# M460_v1 register map
File version: 1.0
Registers are 32-bit, read-write, reset 0x0 unless marked. A register's access mark holds for its fields unless they carry their own. Offsets are from the block's base; [hi:lo] are bit positions; 'fields as' and 'values as' point back to an identical list.

## HSUSBH — USBH Register Map
Base 0x4001A000
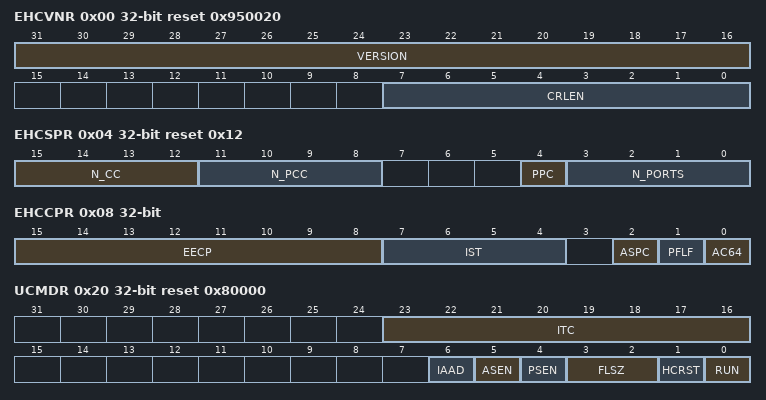
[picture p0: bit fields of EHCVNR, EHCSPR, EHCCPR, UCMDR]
0x00 EHCVNR ro reset 0x950020 — EHCI Version Number Register
  [31:16] VERSION — Host Controller Interface Version Number. This is a two-byte register containing a BCD encoding of the EHCI revision number supported by this host controller. The most significant byte of this register represents a major revision and the least significant byte is the minor revision.
  [7:0] CRLEN — Capability Registers Length. This register is used as an offset to add to register base to find the beginning of the Operational Register Space.
0x04 EHCSPR ro reset 0x12 — EHCI Structural Parameters Register
  [15:12] N_CC — Number of Companion Controller. This field indicates the number of companion controllers associated with this USB 2.0 host controller. A 0 in this field indicates there are no companion host controllers. Port-ownership hand-off is not supported. Only high-speed devices are supported on the host controller root ports. A value larger than 0 in this field indicates there are companion USB 1.1 host controller(s). Port-ownership hand-offs are supported. High, Full- and Low-speed devices are supported on the host controller root ports.
  [11:8] N_PCC — Number of Ports Per Companion Controller. This field indicates the number of ports supported per companion host controller. It is used to indicate the port routing configuration to system software. For example, if N_PORTS has a value of 6 and N_CC has a value of 2 then N_PCC could have a value of 3. The convention is that the first N_PCC ports are assumed to be routed to companion controller 1, the next N_PCC ports to companion controller 2, etc. In the previous example, the N_PCC could have been 4, where the first 4 are routed to companion controller 1 and the last two are routed to companion controller 2. The number in this field must be consistent with N_PORTS and N_CC.
  [4] PPC — Port Power Control. This field indicates whether the host controller implementation includes port power control. A 1 in this bit indicates the ports have port power switches. A 0 in this bit indicates the port do not have port power stitches. The value of this field affects the functionality of the Port Power field in each port status and control register.
  [3:0] N_PORTS — Number of Physical Downstream Ports. This field specifies the number of physical downstream ports implemented on this host controller. The value of this field determines how many port registers are addressable in the Operational Register Space (see Table 2-8). Valid values are in the range of 1H to FH. A 0 in this field is undefined.
0x08 EHCCPR ro — EHCI Capability Parameters Register
  [15:8] EECP — EHCI Extended Capabilities Pointer
    0=No extended capabilities are implemented
  [7:4] IST — Isochronous Scheduling Threshold. This field indicates, relative to the current position of the executing host controller, where software can reliably update the isochronous schedule. When bit [7] is 0, the value of the least significant 3 bits indicates the number of micro-frames a host controller can hold a set of isochronous data structures (one or more) before flushing the state.
  [2] ASPC — Asynchronous Schedule Park Capability
    0=This EHCI host controller doesn't support park feature of high-speed queue heads in the Asynchronous Schedule
  [1] PFLF — Programmable Frame List Flag
    0=System software must use a frame list length of 1024 elements with this EHCI host controller
  [0] AC64 — 64-bit Addressing Capability
    0=Data structure using 32-bit address memory pointers
0x20 UCMDR reset 0x80000 — USB Command Register
  [23:16] ITC — Interrupt Threshold Control (Read/Write). This field is used by system software to select the maximum rate at which the host controller will issue interrupts. The only valid values are defined below. If software writes an invalid value to this register, the results are undefined. Value Maximum Interrupt Interval. Any other value in this register yields undefined results. Software modifications to this bit while HCHalted bit is equal to 0 results in undefined behavior.
    1=1 micro-frame; 2=2 micro-frames; 4=4 micro-frames; 8=8 micro-frames (default, equates to 1 ms); 16=16 micro-frames (2 ms); 32=32 micro-frames (4 ms); 64=64 micro-frames (8 ms)
  [6] IAAD — Interrupt on Asynchronous Advance Doorbell (Read/Write). This bit is used as a doorbell by software to tell the host controller to issue an interrupt the next time it advances asynchronous schedule. Software must write a 1 to this bit to ring the doorbell. When the host controller has evicted all appropriate cached schedule state, it sets the Interrupt on Asynchronous Advance status bit in the USTSR register. If the Interrupt on Asynchronous Advance Enable bit in the USBINTR register is a 1 then the host controller will assert an interrupt at the next interrupt threshold. The host controller sets this bit to a 0 after it has set the Interrupt on Asynchronous Advance status bit in the USTSR register to 1. Software should not write a 1 to this bit when the asynchronous schedule is disabled. Doing so will yield undefined results.
  [5] ASEN — Asynchronous Schedule Enable (Read/Write). This bit controls whether the host controller skips processing the Asynchronous Schedule. Values mean:
    0=Do not process the Asynchronous Schedule; 1=Use the ASYNCLISTADDR register to access the Asynchronous Schedule
  [4] PSEN — Periodic Schedule Enable (Read/Write). This bit controls whether the host controller skips processing the Periodic Schedule. Values mean:
    0=Do not process the Periodic Schedule; 1=Use the PERIODICLISTBASE register to access the Periodic Schedule
  [3:2] FLSZ ro — Frame List Size (Read Only). This field is R/W only if Programmable Frame List Flag in the HCCPARAMS registers is set to a 1. This field specifies the size of the frame list. The size the frame list controls which bits in the Frame Index Register should be used for the Frame List Current index. Values mean:
    0=1024 elements (4096 bytes) Default value; 1=512 elements (2048 bytes); 2=256 elements (1024 bytes) - for resource-constrained environment
  [1] HCRST — Host Controller Reset (Read/Write). This control bit is used by software to reset the host controller. The effects of this on Root Hub registers are similar to a Chip Hardware Reset. When software writes a 1 to this bit, the Host Controller resets its internal pipelines, timers, counters, state machines, etc. to their initial value. Any transaction currently in progress on USB is immediately terminated. A USB reset is not driven on downstream ports. All operational registers, including port registers and port state machines are set to their initial values. Port ownership reverts to the companion host controller(s), with the side effects. Software must reinitialize the host controller in order to return the host controller to an operational state. This bit is set to 0 by the Host Controller when the reset process is complete. Software cannot terminate the reset process early by writing 0 to this register. Software should not set this bit to a 1 when the HCHalted bit in the USTSR register is 0. Attempting to reset an actively running host controller will result in undefined behavior.
  [0] RUN — Run/Stop (Read/Write). When set to a 1, the Host Controller proceeds with execution of the schedule. The Host Controller continues execution as long as this bit is set to a 1. When this bit is set to 0, the Host Controller completes the current and any actively pipelined transactions on the USB and then halts. The Host Controller must halt within 16 micro-frames after software clears the Run bit. The HC Halted bit in the status register indicates when the Host Controller has finished its pending pipelined transactions and has entered the stopped state. Software must not write a 1 to this field unless the host controller is in the Halted state (i.e. HCHalted in the USTSR register is a 1). Doing so will yield undefined results.
    0=Stop; 1=Run
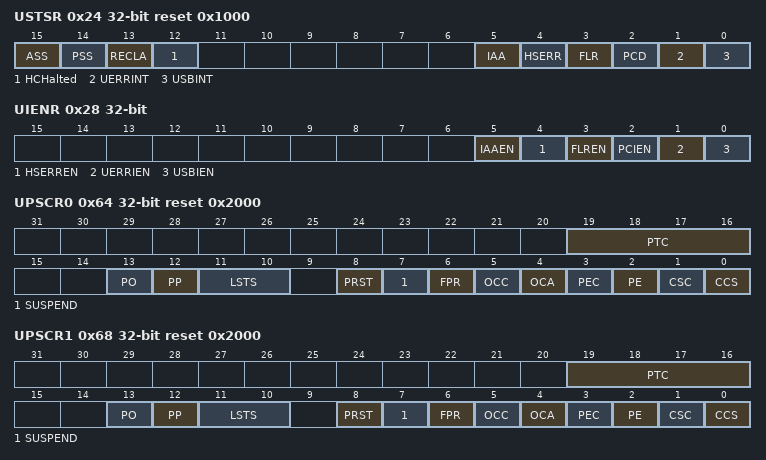
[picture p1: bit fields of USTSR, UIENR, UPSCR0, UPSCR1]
0x24 USTSR reset 0x1000 — USB Status Register
  [15] ASS ro — Asynchronous Schedule Status (Read Only). The bit reports the current real status of the Asynchronous Schedule. If this bit is 0 then the status of them Asynchronous Schedule is disabled. If this bit is a 1 then the status of the Asynchronous Schedule is enabled. The Host Controller is not required to immediately disable or enable the Asynchronous Schedule when software transitions the Asynchronous Schedule Enable bit in the USBCMD register. When this bit and the Asynchronous Schedule Enable bit are the same value, the Asynchronous Schedule is either enabled (1) or disabled (0).
  [14] PSS ro — Periodic Schedule Status (Read Only). The bit reports the current real status of the Periodic Schedule. If this bit is 0 then the status of the Periodic Schedule is disabled. If this bit is a 1 then the status of the Periodic Schedule is enabled. The Host Controller is not required to immediately disable or enable the Periodic Schedule when software transitions the Periodic Schedule Enable bit in the USBCMD register. When this bit and the Periodic Schedule Enable bit are the same value, the Periodic Schedule is either enabled (1) or disabled (0).
  [13] RECLA ro — Reclamation (Read Only). This is a read-only status bit, which is used to detect an empty asynchronous schedule.
  [12] HCHalted ro — HCHalted (Read Only). This bit is 0 whenever the Run/Stop bit is a 1. The Host Controller sets this bit to 1 after it has stopped executing as a result of the Run/Stop bit being set to 0, either by software or by the Host Controller hardware (e.g. internal error).
  [5] IAA — Interrupt on Asynchronous Advance. System software can force the host controller to issue an interrupt the next time the host controller advances the asynchronous schedule by writing a 1 to the Interrupt on Asynchronous Advance Doorbell bit in the USBCMD register. This status bit indicates the assertion of that interrupt source. Note: This bit is cleared by writing 1 to it.
  [4] HSERR — Host System Error. The Host Controller sets this bit to 1 when a serious error occurs during a host system access involving the Host Controller module. Note: This bit is cleared by writing 1 to it.
  [3] FLR — Frame List Rollover. The Host Controller sets this bit to a 1 when the Frame List Index rolls over from its maximum value to 0. The exact value at which the rollover occurs depends on the frame list size. For example, if the frame list size (as programmed in the Frame List Size field of the USBCMD register) is 1024, the Frame Index Register rolls over every time FRINDEX[13] toggles. Similarly, if the size is 512, the Host Controller sets this bit to a 1 every time FRINDEX[12] toggles. Note: This bit is cleared by writing 1 to it.
  [2] PCD — Port Change Detect. The Host Controller sets this bit to a 1 when any port for which the Port Owner bit is set to 0 has a change bit transition from 0 to 1 or a Force Port Resume bit transition from a 0 to a 1 as a result of a J-K transition detected on a suspended port. This bit will also be set as a result of the Connect Status Change being set to a 1 after system software has relinquished ownership of a connected port by writing a 1 to a port's Port Owner bit. This bit is allowed to be maintained in the Auxiliary power well. Alternatively, it is also acceptable that on a D3 to D0 transition of the EHCI HC device, this bit is loaded with the OR of all of the PORTSC change bits (including: Force port resume, overcurrent change, enable/disable change and connect status change). Note: This bit is cleared by writing 1 to it.
  [1] UERRINT — USB Error Interrupt. The Host Controller sets this bit to 1 when completion of a USB transaction results in an error condition (e.g., error counter underflow). If the TD on which the error interrupt occurred also had its IOC bit set, both this bit and USBINT bit are set. Note: This bit is cleared by writing 1 to it.
  [0] USBINT — USB Interrupt. The Host Controller sets this bit to 1 on the completion of a USB transaction, which results in the retirement of a Transfer Descriptor that had its IOC bit set. The Host Controller also sets this bit to 1 when a short packet is detected (actual number of bytes received was less than the expected number of bytes). Note: This bit is cleared by writing 1 to it.
0x28 UIENR — USB Interrupt Enable Register
  [5] IAAEN — Interrupt on Asynchronous Advance Enable or Disable Bit. When this bit is a 1, and the Interrupt on Asynchronous Advance bit in the USTSR register is a 1, the host controller will issue an interrupt at the next interrupt threshold. The interrupt is acknowledged by software clearing the Interrupt on Asynchronous Advance bit.
    0=Interrupt on Asynchronous Advance Disabled; 1=Interrupt on Asynchronous Advance Enabled
  [4] HSERREN — Host System Error Enable or Disable Bit. When this bit is a 1, and the Host System Error Status bit in the USTSR register is a 1, the host controller will issue an interrupt. The interrupt is acknowledged by software clearing the Host System Error bit.
    0=Host System Error interrupt Disabled; 1=Host System Error interrupt Enabled
  [3] FLREN — Frame List Rollover Enable or Disable Bit. When this bit is a 1, and the Frame List Rollover bit in the USTSR register is a 1, the host controller will issue an interrupt. The interrupt is acknowledged by software clearing the Frame List Rollover bit.
    0=Frame List Rollover interrupt Disabled; 1=Frame List Rollover interrupt Enabled
  [2] PCIEN — Port Change Interrupt Enable or Disable Bit. When this bit is a 1, and the Port Change Detect bit in the USTSR register is a 1, the host controller will issue an interrupt. The interrupt is acknowledged by software clearing the Port Change Detect bit.
    0=Port Change interrupt Disabled; 1=Port Change interrupt Enabled
  [1] UERRIEN — USB Error Interrupt Enable or Disable Bit. When this bit is a 1, and the UERRINT bit in the USTSR register is a 1, the host controller will issue an interrupt at the next interrupt threshold. The interrupt is acknowledged by software clearing the UERRINT bit.
    0=USB Error interrupt Disabled; 1=USB Error interrupt Enabled
  [0] USBIEN — USB Interrupt Enable or Disable Bit. When this bit is a 1, and the USBINT bit in the USTSR register is a 1, the host controller will issue an interrupt at the next interrupt threshold. The interrupt is acknowledged by software clearing the USBINT bit.
    0=USB interrupt Disabled; 1=USB interrupt Enabled
0x2C UFINDR — USB Frame Index Register
  [13:0] FI — Frame Index. The value in this register increment at the end of each time frame (e.g. micro-frame). Bits [N:3] are used for the Frame List current index. This means that each location of the frame list is accessed 8 times (frames or micro-frames) before moving to the next index. The following illustrates values of N based on the value of the Frame List Size field in the USBCMD register. FLSZ (UCMDR[3:2] Number Elements N. 0x0 1024 12. 0x1 512 11. 0x2 256 10. 0x3 Reserved
0x34 UPFLBAR — USB Periodic Frame List Base Address Register
  [31:12] BADDR — Base Address. These bits correspond to memory address signals [31:12], respectively.
0x38 UCALAR — USB Current Asynchronous List Address Register
  [31:5] LPL — Link Pointer Low. These bits correspond to memory address signals [31:5], respectively. This field may only reference a Queue Head (QH).
0x3C UASSTR — USB Asynchronous Schedule Sleep Timer Register
  [11:0] ASSTMR — Asynchronous Schedule Sleep Timer. This field defines the AsyncSchedSleepTime of EHCI spec. The asynchronous schedule sleep timer is used to control how often the host controller fetches asynchronous schedule list from system memory while the asynchronous schedule is empty. The default value of this timer is 12'h0 and can be set to 12'hBD6. Because this timer is implemented in UTMI clock (30 MHz) domain, the default sleeping time will be about 100us.
0x60 UCFGR — USB Configure Flag Register
  [0] CF — Configure Flag. Host software sets this bit as the last action in its process of configuring the Host Controller. This bit controls the default port-routing control logic. Bit values and side-effects are listed below.
    0=Port routing control logic default-routes each port to an implementation dependent classic host controller; 1=Port routing control logic default-routes all ports to this host controller
0x64 UPSCR0 reset 0x2000 — USB Port 0 Status and Control Register
  [19:16] PTC — Port Test Control (Read/Write). When this field is 0, the port is NOT operating in a test mode. A non-zero value indicates that it is operating in test mode and the specific test mode is indicated by the specific value. The encoding of the test mode bits are (0x6 ~ 0xF are reserved): Bits Test Mode
    0=Test mode not enabled; 1=Test J_STATE; 2=Test K_STATE; 3=Test SE0_NAK; 4=Test Packet; 5=Test FORCE_ENABLE
  [13] PO — Port Owner (Read/Write). This bit unconditionally goes to a 0b when the Configured bit in the CONFIGFLAG register makes a 0 to 1 transition. This bit unconditionally goes to 1 whenever the Configured bit is 0. System software uses this field to release ownership of the port to a selected host controller (in the event that the attached device is not a high-speed device). Software writes a 1 to this bit when the attached device is not a high-speed device. A 1 in this bit means that a companion host controller owns and controls the port.
  [12] PP — Port Power. When an overcurrent condition is detected on a powered port and PPC is a 1, the PP bit in each affected port may be transitioned by the host controller from a 1 to 0 (removing power from the port).
  [11:10] LSTS ro — Line Status (Read Only). These bits reflect the current logical levels of the D+ (bit 11) and D- (bit 10) signal lines. These bits are used for detection of low-speed USB devices prior to the port reset and enable sequence. This field is valid only when the port enable bit is 0 and the current connect status bit is set to a 1. The encoding of the bits are: Bits[11:10] USB State Interpretation. This value of this field is undefined if Port Power is 0.
    0=SE0 Not Low-speed device, perform EHCI reset; 1=K-state Low-speed device, release ownership of port; 2=J-state Not Low-speed device, perform EHCI reset; 3=Undefined Not Low-speed device, perform EHCI reset
  [8] PRST — Port Reset (Read/Write). When software writes a 1 to this bit (from a 0), the bus reset sequence as defined in the USB Specification Revision 2.0 is started. Software writes a 0 to this bit to terminate the bus reset sequence. Software must keep this bit at a 1 long enough to ensure the reset sequence, as specified in the USB Specification Revision 2.0, completes. Note: when software writes this bit to a 1, it must also write a 0 to the Port Enable bit. Note that when software writes a 0 to this bit there may be a delay before the bit status changes to a 0. The bit status will not read as a 0 until after the reset has completed. If the port is in high-speed mode after reset is complete, the host controller will automatically enable this port (e.g. set the Port Enable bit to a 1). A host controller must terminate the reset and stabilize the state of the port within 2 milliseconds of software transitioning this bit from a 1 to a 0. For example: if the port detects that the attached device is high-speed during reset, then the host controller must have the port in the enabled state within 2ms of software writing this bit to a 0. The HCHalted bit in the USTSR register should be a 0 before software attempts to use this bit. The host controller may hold Port Reset asserted to a 1 when the HCHalted bit is a 1. This field is 0 if Port Power is 0.
    0=Port is not in Reset; 1=Port is in Reset
  [7] SUSPEND — Suspend (Read/Write). Port Enabled Bit and Suspend bit of this register define the port states as follows:
    0=Port Disable. Port not in suspend state; 1=Port Disable. Port in suspend state; 2=Port Enable; 3=Port Suspend
  [6] FPR — Force Port Resume (Read/Write). This functionality defined for manipulating this bit depends on the value of the Suspend bit. For example, if the port is not suspended (Suspend and Enabled bits are a 1) and software transitions this bit to a 1, then the effects on the bus are undefined. Software sets this bit to a 1 to drive resume signaling. The Host Controller sets this bit to a 1 if a J-to-K transition is detected while the port is in the Suspend state. When this bit transitions to a 1 because a J-to-K transition is detected, the Port Change Detect bit in the USTSR register is also set to a 1. If software sets this bit to a 1, the host controller must not set the Port Change Detect bit. Note that when the EHCI controller owns the port, the resume sequence follows the defined sequence documented in the USB Specification Revision 2.0. The resume signaling (Full-speed 'K') is driven on the port as long as this bit remains a 1. Software must appropriately time the Resume and set this bit to a 0 when the appropriate amount of time has elapsed. Writing a 0 (from 1) causes the port to return to high-speed mode (forcing the bus below the port into a high-speed idle). This bit will remain a 1 until the port has switched to the high-speed idle. The host controller must complete this transition within 2 milliseconds of software setting this bit to a 0. This field is 0 if Port Power is 0.
    0=No resume (K-state) detected/driven on port; 1=Resume detected/driven on port
  [5] OCC — Overcurrent Change. Note: This bit is cleared by writing 1 to it.
    1=This bit gets set to a 1 when there is a change to Overcurrent Active. Software clears this bit by writing a 1 to this bit position
  [4] OCA ro — Overcurrent Active (Read Only). This bit will automatically transition from a 1 to a 0 when the overcurrent condition is removed.
    0=This port does not have an overcurrent condition; 1=This port currently has an overcurrent condition
  [3] PEC — Port Enable/Disable Change. For the root hub, this bit gets set to a 1 only when a port is disabled due to the appropriate conditions existing at the EOF2 point (See Chapter 11 of the USB Specification for the definition of a Port Error). Software clears this bit by writing a 1 to it. This field is 0 if Port Power is 0. Note: This bit is cleared by writing 1 to it.
    0=No change; 1=Port enabled/disabled status has changed
  [2] PE — Port Enabled/Disabled (Read/Write). Ports can only be enabled by the host controller as a part of the reset and enable. Software cannot enable a port by writing a 1 to this field. The host controller will only set this bit to a 1 when the reset sequence determines that the attached device is a high-speed device. Ports can be disabled by either a fault condition (disconnect event or other fault condition) or by host software. Note that the bit status does not change until the port state actually changes. There may be a delay in disabling or enabling a port due to other host controller and bus events. When the port is disabled (0b) downstream propagation of data is blocked on this port, except for reset. This field is 0 if Port Power is 0.
    0=Port Disabled; 1=Port Enabled
  [1] CSC — Connect Status Change (Read/Write). Indicate a change has occurred in the port's Current Connect Status. The host controller sets this bit for all changes to the port device connect status, even if system software has not cleared an existing connect status change. For example, the insertion status changes twice before system software has cleared the changed condition, hub hardware will be 'setting' an already-set bit (i.e., the bit will remain set). Software sets this bit to 0 by writing a 1 to it. This field is 0 if Port Power is 0.
    0=No change; 1=Change in Current Connect Status
  [0] CCS ro — Current Connect Status (Read Only). This value reflects the current state of the port, and may not correspond directly to the event that caused the Connect Status Change bit (Bit 1) to be set. This field is 0 if Port Power is 0.
    0=No device is present; 1=Device is present on port
0x68 UPSCR1 reset 0x2000 — USB Port 1 Status and Control Register
  fields as UPSCR0
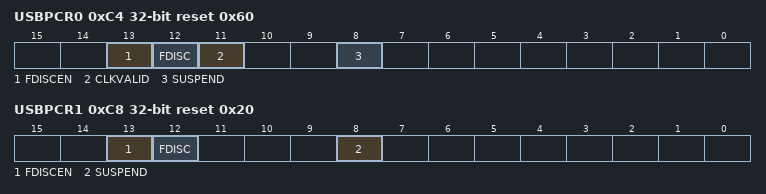
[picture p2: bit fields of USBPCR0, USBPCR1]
0xC4 USBPCR0 reset 0x60 — USB PHY 0 Control Register
  [13] FDISCEN — Force Disconnection Function Enable Bit. This bit is used to enable Force Disconnection Function (FDISC).
    0=Force Disconnection Function Disabled; 1=Force Disconnection Function Enabled
  [12] FDISC — Force Disconnection Function. This bit is used to force the device to disconnect without really removing the device from the port. This bit is valid only if FDISCEN is asserted.
    0=The device is not forced to be disconnected; 1=The device is forced to disconnected
  [11] CLKVALID — UTMI Clock Valid. This bit is a flag to indicate if the UTMI clock from USB 2.0 PHY is ready. Software program must prevent to write other control registers before this UTMI clock valid flag is active.
    0=UTMI clock is not valid; 1=UTMI clock is valid
  [8] SUSPEND — Suspend Assertion. This bit controls the suspend mode of USB PHY 0. While PHY was suspended, all circuits of PHY were powered down and outputs are tri-state. This bit is 1'b0 in default. This means the USB PHY 0 is suspended in default. It is necessary to set this bit 1'b1 to make USB PHY 0 leave suspend mode before doing configuration of USB host.
    0=USB PHY 0 was suspended; 1=USB PHY 0 was not suspended
0xC8 USBPCR1 reset 0x20 — USB PHY 1 Control Register
  [13] FDISCEN — Force Disconnection Function Enable. This bit is used to enable Force Disconnection Function (FDISC).
    values as USBPCR0.FDISCEN
  [12] FDISC — Force Disconnection Function. This bit is used to force the device to disconnect without really removing the device from the port. This bit is valid only if FDISCEN is asserted.
    0=The device is not forced to disconnect; 1=The device is forced to disconnect
  [8] SUSPEND — Suspend Assertion. This bit controls the suspend mode of USB PHY 1. While PHY was suspended, all circuits of PHY were powered down and outputs are tri-state. This bit is 1'b0 in default. This means the USB PHY 0 is suspended in default. It is necessary to set this bit 1'b1 to make USB PHY 0 leave suspend mode before doing configuration of USB host.
    0=USB PHY 1 suspended; 1=USB PHY 1 not suspended
